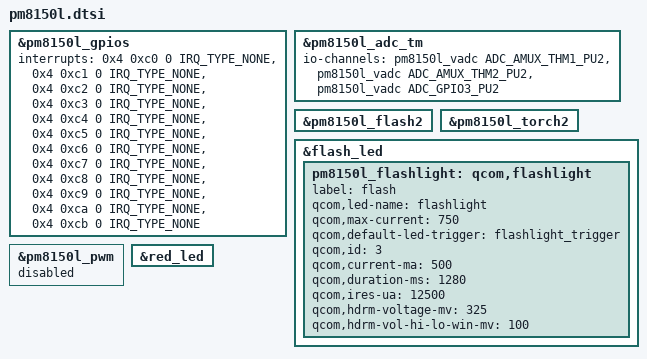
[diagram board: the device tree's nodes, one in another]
&pm8150l_gpios {
	interrupts = <0x4 0xc0 0 IRQ_TYPE_NONE>,
			<0x4 0xc1 0 IRQ_TYPE_NONE>,
			<0x4 0xc2 0 IRQ_TYPE_NONE>,
			<0x4 0xc3 0 IRQ_TYPE_NONE>,
			<0x4 0xc4 0 IRQ_TYPE_NONE>,
			<0x4 0xc5 0 IRQ_TYPE_NONE>,
			<0x4 0xc6 0 IRQ_TYPE_NONE>,
			<0x4 0xc7 0 IRQ_TYPE_NONE>,
			<0x4 0xc8 0 IRQ_TYPE_NONE>,
			<0x4 0xc9 0 IRQ_TYPE_NONE>,
			<0x4 0xca 0 IRQ_TYPE_NONE>,
			<0x4 0xcb 0 IRQ_TYPE_NONE>;
	interrupt-names = "pm8150l_gpio1", "pm8150l_gpio2",
			"pm8150l_gpio3", "pm8150l_gpio4",
			"pm8150l_gpio5", "pm8150l_gpio6",
			"pm8150l_gpio7",
			"pm8150l_gpio8", "pm8150l_gpio9",
			"pm8150l_gpio10", "pm8150l_gpio11",
			"pm8150l_gpio12";
	/delete-property/ qcom,gpios-disallowed;
};

&pm8150l_adc_tm {
	io-channels = <&pm8150l_vadc ADC_AMUX_THM1_PU2>,
			<&pm8150l_vadc ADC_AMUX_THM2_PU2>,
			<&pm8150l_vadc ADC_GPIO3_PU2>;
};

&pm8150l_flash2 {
	status = "ok";
};

&pm8150l_torch2 {
	status = "ok";
};

&flash_led {
	pm8150l_flashlight: qcom,flashlight {
		label = "flash";
		qcom,led-name = "flashlight";
		qcom,max-current = <750>;
		qcom,default-led-trigger = "flashlight_trigger";
		qcom,id = <3>;
		qcom,current-ma = <500>;
		qcom,duration-ms = <1280>;
		qcom,ires-ua = <12500>;
		qcom,hdrm-voltage-mv = <325>;
		qcom,hdrm-vol-hi-lo-win-mv = <100>;
	};
};

&pm8150l_pwm {
	status = "disabled";
};

&red_led {
	/delete-property/ linux,default-trigger;
};
